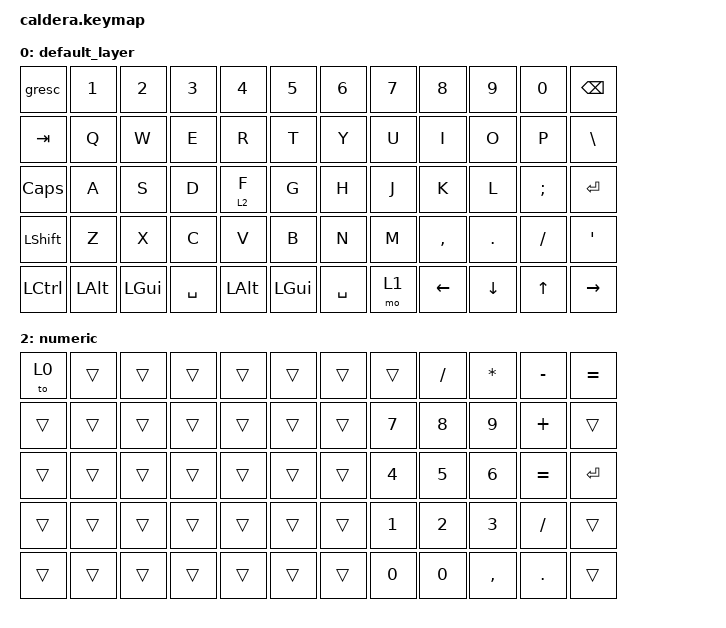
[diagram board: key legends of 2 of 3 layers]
#include <behaviors.dtsi>
#include <dt-bindings/zmk/bt.h>
#include <dt-bindings/zmk/keys.h>

/ {
    keymap {
        compatible = "zmk,keymap";

        default_layer {
            // ---------------------------------------------------------------------------------
            // | `ESC |  1  |  2  |  3  |  4  |  5  |     |  6  |  7  |  8  |  9  |  0  | BKSP |
            // |  TAB |  Q  |  W  |  E  |  R  |  T  |     |  Y  |  U  |  I  |  O  |  P  |  \   |
            // | CAPS |  A  |  S  |  D  |  F  |  G  |     |  H  |  J  |  K  |  L  |  ;  |  ENT |
            // | SHFT |  Z  |  X  |  C  |  V  |  B  |     |  N  |  M  |  ,  |  .  |  /  | APOS |
            // | CTRL | ALT | GUI | SPC | SPC | SPC |     | SPC | LOW |LARW |DARW |UARW | RARW |

            bindings = <
&gresc     &kp N1    &kp N2    &kp N3     &kp N4    &kp N5      &kp N6     &kp N7  &kp N8          &kp N9          &kp N0        &kp BSPC
&kp TAB    &kp Q     &kp W     &kp E      &kp R     &kp T       &kp Y      &kp U   &kp I           &kp O           &kp P         &kp BSLH
&kp CAPS   &kp A     &kp S     &kp D      &lt 2 F   &kp G       &kp H      &kp J   &kp K           &kp L           &kp SEMI      &kp RET
&kp LSHFT  &kp Z     &kp X     &kp C      &kp V     &kp B       &kp N      &kp M   &kp COMMA       &kp DOT         &kp FSLH      &kp APOS
&kp LCTRL  &kp LALT  &kp LGUI  &kp SPACE  &kp LALT  &kp LGUI    &kp SPACE  &mo 1   &kp LEFT_ARROW  &kp DOWN_ARROW  &kp UP_ARROW  &kp RIGHT_ARROW
            >;
        };

        lower_layer {
            // ------------------------------------------------------------------------------------------------------------
            // |       |  F1   |  F2   |  F3   |  F4   |  F5   |          |  F6   |  F7   |  F8   |  F9   |       |       |
            // |       |  BT1  |  BT2  |  BT3  |  BT4  |  BT5  |          | BTCLR |       |       |       |       |       |
            // |       |       |       |   (   |   )   |       |          |       |   [   |   ]   |   -   |   =   |       |
            // |       |       |       |       |       |       |          |   ~   |       |       |       |       |       |

            bindings = <
&to 0   &kp F1        &kp F2        &kp F3        &kp F4        &kp F5          &kp F6      &kp F7    &kp F8    &kp F9     &trans     &trans
&trans  &bt BT_SEL 0  &bt BT_SEL 1  &bt BT_SEL 2  &bt BT_SEL 3  &bt BT_SEL 4    &bt BT_CLR  &trans    &trans    &trans     &trans     &trans
&trans  &trans        &trans        &kp LPAR      &kp RPAR      &trans          &kp TILDE   &kp LBKT  &kp RBKT  &kp MINUS  &kp EQUAL  &trans
&trans  &trans        &trans        &trans        &trans        &trans          &trans      &trans    &trans    &trans     &trans     &trans
            >;
        };

        numeric {
            bindings = <
&to 0   &trans  &trans  &trans  &trans  &trans    &trans  &trans  &kp FSLH      &kp ASTERISK  &kp MINUS   &kp EQUAL
&trans  &trans  &trans  &trans  &trans  &trans    &trans  &kp N7  &kp N8        &kp N9        &kp PLUS    &trans
&trans  &trans  &trans  &trans  &trans  &trans    &trans  &kp N4  &kp N5        &kp N6        &kp EQUAL   &kp ENTER
&trans  &trans  &trans  &trans  &trans  &trans    &trans  &kp N1  &kp N2        &kp N3        &kp SLASH   &trans
&trans  &trans  &trans  &trans  &trans  &trans    &trans  &kp N0  &kp NUMBER_0  &kp COMMA     &kp PERIOD  &trans
            >;
        };
    };
};
